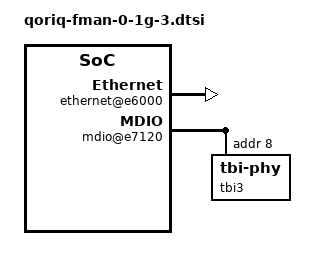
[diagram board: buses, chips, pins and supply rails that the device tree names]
// SPDX-License-Identifier: (GPL-2.0+ OR BSD-3-Clause)
/*
 * QorIQ FMan 1g port #3 device tree stub [ controller @ offset 0x400000 ]
 *
 * Copyright 2011 - 2015 Freescale Semiconductor Inc.
 * Copyright 2020 NXP
 *
 */

fman@400000 {
	fman0_rx_0x0b: port@8b000 {
		cell-index = <0xb>;
		compatible = "fsl,fman-v2-port-rx";
		reg = <0x8b000 0x1000>;
	};

	fman0_tx_0x2b: port@ab000 {
		cell-index = <0x2b>;
		compatible = "fsl,fman-v2-port-tx";
		reg = <0xab000 0x1000>;
	};

	ethernet@e6000 {
		cell-index = <3>;
		compatible = "fsl,fman-dtsec";
		reg = <0xe6000 0x1000>;
		fsl,fman-ports = <&fman0_rx_0x0b &fman0_tx_0x2b>;
		tbi-handle = <&tbi3>;
		ptp-timer = <&ptp_timer0>;
	};

	mdio@e7120 {
		#address-cells = <1>;
		#size-cells = <0>;
		compatible = "fsl,fman-mdio";
		reg = <0xe7120 0xee0>;

		tbi3: tbi-phy@8 {
			reg = <0x8>;
			device_type = "tbi-phy";
		};
	};
};
